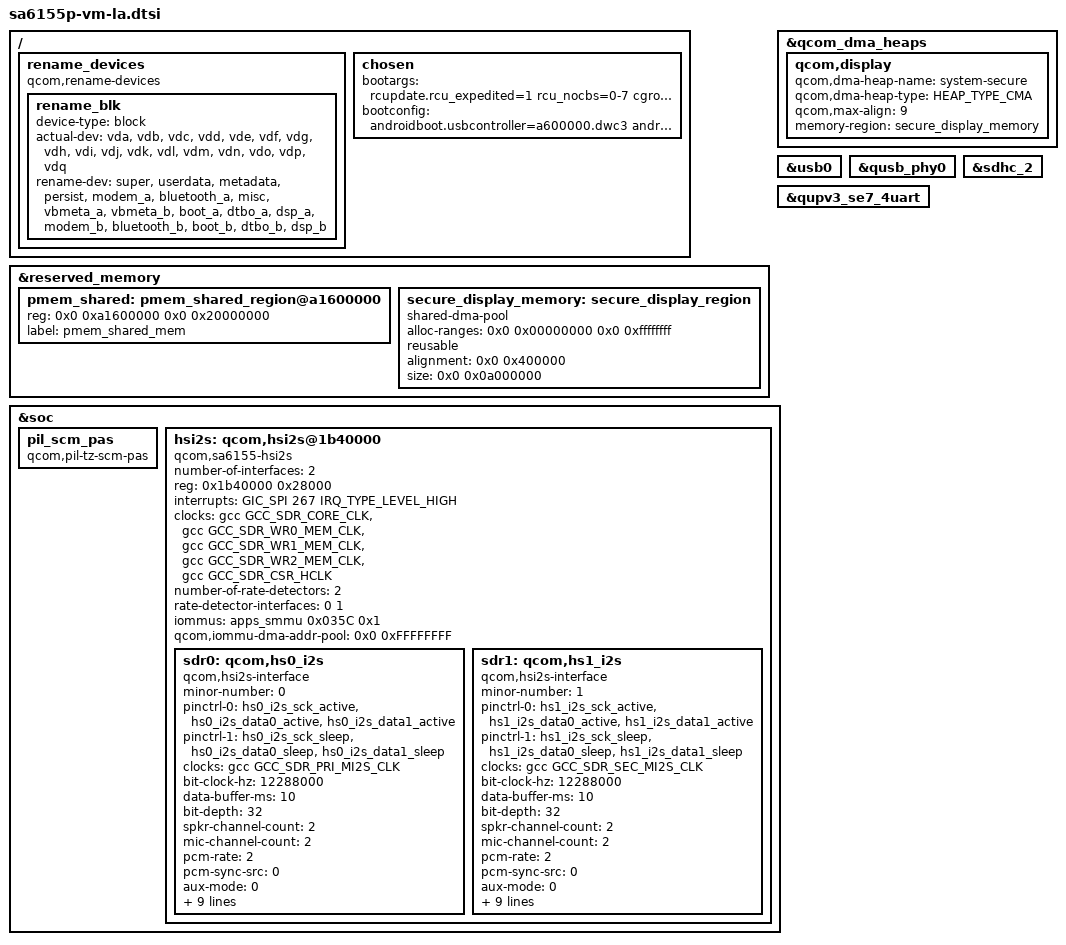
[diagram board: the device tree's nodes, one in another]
&reserved_memory {
	/delete-node/ pmem_shared_region;
	pmem_shared: pmem_shared_region@a1600000 {
		reg = <0x0 0xa1600000 0x0 0x20000000>;
		label = "pmem_shared_mem";
	};

	secure_display_memory: secure_display_region {
		compatible = "shared-dma-pool";
		alloc-ranges = <0x0 0x00000000 0x0 0xffffffff>;
		reusable;
		alignment = <0x0 0x400000>;
		size = <0x0 0x0a000000>;
	};
};

/ {
	rename_devices: rename_devices {
		compatible = "qcom,rename-devices";
		rename_blk: rename_blk {
			device-type = "block";
			actual-dev = "vda", "vdb", "vdc",
					"vdd", "vde", "vdf",
					"vdg", "vdh", "vdi",
					"vdj", "vdk", "vdl",
					"vdm", "vdn", "vdo",
					"vdp", "vdq";
			rename-dev = "super", "userdata", "metadata",
					"persist", "modem_a","bluetooth_a",
					"misc", "vbmeta_a", "vbmeta_b",
					"boot_a", "dtbo_a","dsp_a",
					"modem_b", "bluetooth_b", "boot_b",
					"dtbo_b", "dsp_b";
		};
	};

	chosen {
		bootargs = "rcupdate.rcu_expedited=1 rcu_nocbs=0-7 cgroup.memory=nokmem,nosocket androidboot.usbcontroller=a600000.dwc3 androidboot.fstab_suffix=gen3.qcom";
		bootconfig = "androidboot.usbcontroller=a600000.dwc3 androidboot.fstab_suffix=gen3.qcom";
	};
};

&qcom_dma_heaps {
	qcom,display {
		qcom,dma-heap-name = "system-secure";
		qcom,dma-heap-type = <HEAP_TYPE_CMA>;
		qcom,max-align = <9>;
		memory-region = <&secure_display_memory>;
	};
};

&usb0 {
	status = "ok";
};

&qusb_phy0 {
	status = "ok";
};

&sdhc_2 {
	status = "ok";
};

&qupv3_se7_4uart {
	status = "ok";
};

&soc {
	pil_scm_pas {
		compatible = "qcom,pil-tz-scm-pas";
	};

	hsi2s: qcom,hsi2s@1b40000 {
		compatible = "qcom,sa6155-hsi2s", "qcom,hsi2s";
		number-of-interfaces = <2>;
		reg = <0x1b40000 0x28000>;
		reg-names = "lpa_if";
		interrupts = <GIC_SPI 267 IRQ_TYPE_LEVEL_HIGH>;
		clocks = <&gcc GCC_SDR_CORE_CLK>,
			 <&gcc GCC_SDR_WR0_MEM_CLK>,
			 <&gcc GCC_SDR_WR1_MEM_CLK>,
			 <&gcc GCC_SDR_WR2_MEM_CLK>,
			 <&gcc GCC_SDR_CSR_HCLK>;
		clock-names = "core_clk", "wr0_mem_clk",
			      "wr1_mem_clk", "wr2_mem_clk",
			      "csr_hclk";
		number-of-rate-detectors = <2>;
		rate-detector-interfaces = <0 1>;
		iommus = <&apps_smmu 0x035C 0x1>;
		qcom,iommu-dma-addr-pool = <0x0 0xFFFFFFFF>;

		sdr0: qcom,hs0_i2s {
			compatible = "qcom,hsi2s-interface";
			minor-number = <0>;
			pinctrl-names = "default", "sleep";
			pinctrl-0 = <&hs0_i2s_sck_active &hs0_i2s_data0_active
				     &hs0_i2s_data1_active>;
			pinctrl-1 = <&hs0_i2s_sck_sleep &hs0_i2s_data0_sleep
				     &hs0_i2s_data1_sleep>;
			clocks = <&gcc GCC_SDR_PRI_MI2S_CLK>;
			clock-names = "pri_mi2s_clk";
			bit-clock-hz = <12288000>;
			data-buffer-ms = <10>;
			bit-depth = <32>;
			spkr-channel-count = <2>;
			mic-channel-count = <2>;
			pcm-rate = <2>;
			pcm-sync-src = <0>;
			aux-mode = <0>;
			rpcm-width = <1>;
			tpcm-width = <1>;
			enable-tdm = <1>;
			tdm-rate = <32>;
			tdm-rpcm-width = <16>;
			tdm-tpcm-width = <16>;
			tdm-sync-delay = <2>;
			tdm-inv-sync = <0>;
			pcm-lane-config = <1>;
		};

		sdr1: qcom,hs1_i2s {
			compatible = "qcom,hsi2s-interface";
			minor-number = <1>;
			pinctrl-names = "default", "sleep";
			pinctrl-0 = <&hs1_i2s_sck_active &hs1_i2s_data0_active
				     &hs1_i2s_data1_active>;
			pinctrl-1 = <&hs1_i2s_sck_sleep &hs1_i2s_data0_sleep
				     &hs1_i2s_data1_sleep>;
			clocks = <&gcc GCC_SDR_SEC_MI2S_CLK>;
			clock-names = "sec_mi2s_clk";
			bit-clock-hz = <12288000>;
			data-buffer-ms = <10>;
			bit-depth = <32>;
			spkr-channel-count = <2>;
			mic-channel-count = <2>;
			pcm-rate = <2>;
			pcm-sync-src = <0>;
			aux-mode = <0>;
			rpcm-width = <1>;
			tpcm-width = <1>;
			enable-tdm = <1>;
			tdm-rate = <32>;
			tdm-rpcm-width = <16>;
			tdm-tpcm-width = <16>;
			tdm-sync-delay = <2>;
			tdm-inv-sync = <0>;
			pcm-lane-config = <1>;
		};
	};
};
